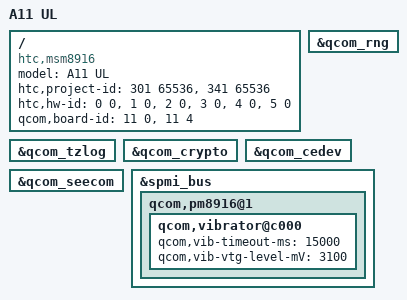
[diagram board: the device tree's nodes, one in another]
/* Copyright (c) 2014, The Linux Foundation. All rights reserved.
*
* This program is free software; you can redistribute it and/or modify
* it under the terms of the GNU General Public License version 2 and
* only version 2 as published by the Free Software Foundation.
*
* This program is distributed in the hope that it will be useful,
* but WITHOUT ANY WARRANTY; without even the implied warranty of
* MERCHANTABILITY or FITNESS FOR A PARTICULAR PURPOSE.  See the
* GNU General Public License for more details.
*/

/dts-v1/;

#include "msm8916-a11ul.dtsi"
#include "msm8916-memory.dtsi"
#include "msm8916-remove-cp-mm.dtsi"

/ {
	model = "A11 UL";
	compatible = "htc,msm8916", "htc,a11ul", "qcom,msm8916-mtp", "qcom,msm8916", "qcom,mtp";
	htc,project-id = <301 65536>,<341 65536>;   /* htc,project-id = <PID soc_vision> */
	htc,hw-id = <0 0>,<1 0>,<2 0>,<3 0>,<4 0>,<5 0>;   /* htc,hw-id = <PCBID (Reserved)> */
	qcom,board-id = <11 0> , <11 4>;
};

&qcom_tzlog {
	status = "okay";
};

&qcom_rng {
	status = "okay";
};

&qcom_crypto {
	status = "okay";
};

&qcom_cedev {
	status = "okay";
};

&qcom_seecom {
	status = "okay";
};

&spmi_bus {
	qcom,pm8916@1 {
		qcom,vibrator@c000 {
			status = "okay";
			qcom,vib-timeout-ms = <15000>;
			qcom,vib-vtg-level-mV = <3100>;
		};
	};
};
